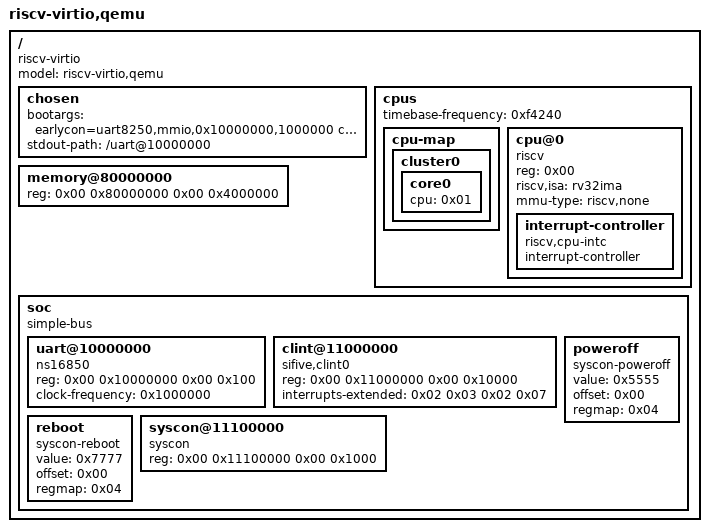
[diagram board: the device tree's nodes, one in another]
/dts-v1/;

/ {
	#address-cells = <0x02>;
	#size-cells = <0x02>;
	compatible = "riscv-virtio";
	model = "riscv-virtio,qemu";

	chosen {
		// bootargs = "earlycon=uart8250,mmio,0x10000000,1000000 console=ttyS0";
		bootargs = "earlycon=uart8250,mmio,0x10000000,1000000 console=ttyS0";
		stdout-path = "/uart@10000000";
	};

	cpus {
		#address-cells = <0x01>;
		#size-cells = <0x00>;
		timebase-frequency = <0xf4240>;

		cpu-map {
			cluster0 {
				core0 {
					cpu = <0x01>;
				};
			};
		};

		cpu@0 {
			phandle = <0x01>;
			device_type = "cpu";
			reg = <0x00>;
			status = "okay";
			compatible = "riscv";
			riscv,isa = "rv32ima";
			mmu-type = "riscv,none";

			interrupt-controller {
				#interrupt-cells = <0x01>;
				interrupt-controller;
				compatible = "riscv,cpu-intc";
				phandle = <0x02>;
			};
		};
	};

	memory@80000000 {
		device_type = "memory";
		reg = <0x00 0x80000000 0x00 0x4000000>;
	};

	soc {
		#address-cells = <0x02>;
		#size-cells = <0x02>;
		compatible = "simple-bus";
		ranges;

		uart@10000000 {
			reg = <0x00 0x10000000 0x00 0x100>;

			clock-frequency = <0x1000000>;
			compatible = "ns16850";
		};

		clint@11000000 {
			reg = <0x00 0x11000000 0x00 0x10000>;

			interrupts-extended = <0x02 0x03 0x02 0x07>;
			compatible = "sifive,clint0\0riscv,clint0";
		};

		poweroff {
			value = <0x5555>;
			offset = <0x00>;
			regmap = <0x04>;
			compatible = "syscon-poweroff";
		};

		reboot {
			value = <0x7777>;
			offset = <0x00>;
			regmap = <0x04>;
			compatible = "syscon-reboot";
		};

		syscon@11100000 {
			reg = <0x00 0x11100000 0x00 0x1000>;
			
			phandle = <0x04>;
			compatible = "syscon";
		};
	};
};
